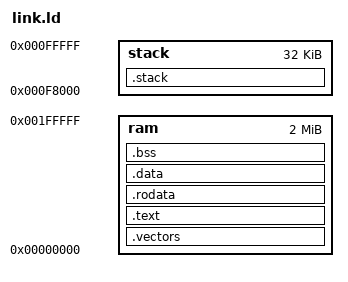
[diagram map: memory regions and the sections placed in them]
/* Copyright lowRISC contributors.
   Licensed under the Apache License, Version 2.0, see LICENSE for details.
   SPDX-License-Identifier: Apache-2.0 */

OUTPUT_ARCH(riscv)

MEMORY
{
    /* 992 kB should be enough for anybody... */
    ram         : ORIGIN = 0x00000000, LENGTH = 0x200000 /* 992 kB */
    stack       : ORIGIN = 0x000F8000, LENGTH = 0x8000  /* 32 kB */
}

/* Stack information variables */
_min_stack      = 0x2000;   /* 8K - minimum stack space to reserve */
_stack_len     = LENGTH(stack);
_stack_start   = ORIGIN(stack) + LENGTH(stack);

_entry_point = _vectors_start + 0x80;
ENTRY(_entry_point)


SECTIONS
{
    .vectors :
    {
		_vectors_start = .;
        KEEP(*(.vectors))
		_vectors_end = .;
    } > ram

    .text : {
        . = 0x80;
        *(.text)
        *(.text.*)
    }  > ram

    .rodata : {
        /* Small RO data before large RO data */
        *(.srodata)
        *(.srodata.*)
        *(.rodata);
        *(.rodata.*)
    } > ram

    .data : {
        /* Small data before large data */
        *(.sdata)
        *(.sdata.*)
        *(.data);
        *(.data.*)
    } > ram

    .bss :
    {
        _bss_start = .;
        /* Small BSS before large BSS */
        *(.sbss)
        *(.sbss.*)
        *(.bss)
        *(.bss.*)
        *(COMMON)
        _bss_end = .;
    } > ram

    /* ensure there is enough room for stack */
    .stack (NOLOAD): {
        . = . + _min_stack ;
        stack = . ;
        _stack = . ;
    } > stack
}
